VERSION ""

NS_ :

BS_:

BU_: Receiver ChassisBus VehicleBus PartyBus

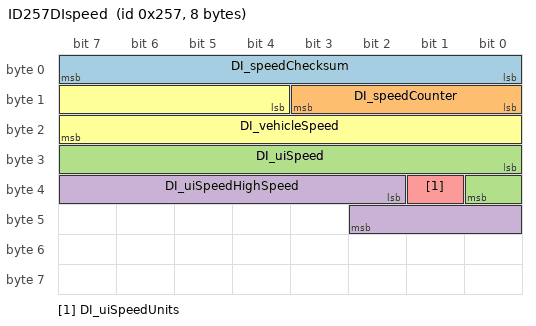
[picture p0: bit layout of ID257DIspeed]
BO_ 599 ID257DIspeed: 8 VehicleBus
 SG_ DI_speedChecksum : 0|8@1+ (1,0) [0|255] ""  Receiver
 SG_ DI_speedCounter : 8|4@1+ (1,0) [0|15] ""  Receiver
 SG_ DI_uiSpeed : 24|9@1+ (1,0) [0|510] ""  Receiver
 SG_ DI_uiSpeedHighSpeed : 34|9@1+ (1,0) [0|510] ""  Receiver
 SG_ DI_uiSpeedUnits : 33|1@1+ (1,0) [0|1] ""  Receiver
 SG_ DI_vehicleSpeed : 12|12@1+ (0.08,-40) [-40|285] "kph"  Receiver
